VERSION ""

NS_ :

BS_:

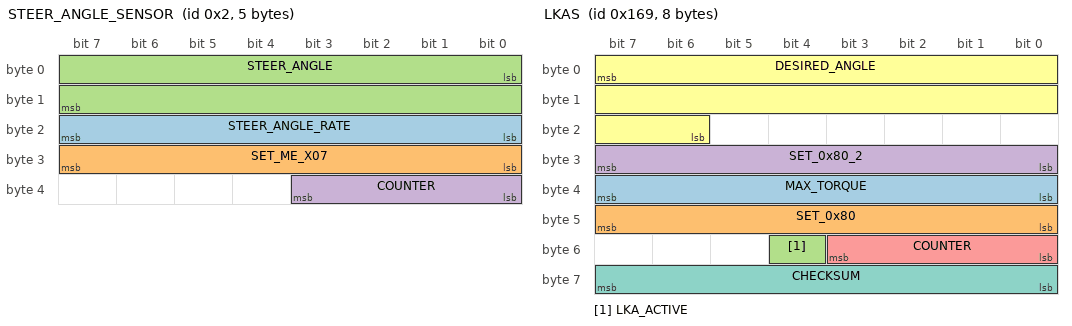
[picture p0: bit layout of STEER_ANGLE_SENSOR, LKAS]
BO_ 2 STEER_ANGLE_SENSOR: 5 XXX
 SG_ STEER_ANGLE_RATE : 16|8@1+ (1,0) [0|255] "" XXX
 SG_ SET_ME_X07 : 24|8@1+ (1,0) [0|255] "" XXX
 SG_ STEER_ANGLE : 0|16@1- (-0.1,0) [0|65535] "" XXX
 SG_ COUNTER : 32|4@1+ (1,0) [0|15] "" XXX

BO_ 361 LKAS: 8 XXX
 SG_ MAX_TORQUE : 39|8@0+ (0.01,0) [0|255] "Nm" XXX
 SG_ SET_0x80 : 47|8@0+ (1,0) [0|255] "" XXX
 SG_ LKA_ACTIVE : 52|1@0+ (1,0) [0|15] "" XXX
 SG_ SET_0x80_2 : 31|8@0+ (1,0) [0|255] "" XXX
 SG_ COUNTER : 51|4@0+ (1,0) [0|15] "" XXX
 SG_ DESIRED_ANGLE : 7|18@0+ (-0.01,1310) [-1311.43|1310] "" XXX
 SG_ CHECKSUM : 63|8@0+ (1,0) [0|255] "" XXX

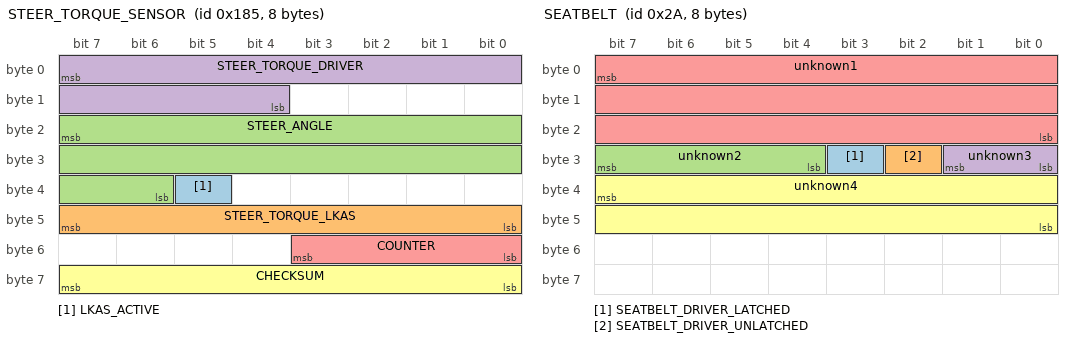
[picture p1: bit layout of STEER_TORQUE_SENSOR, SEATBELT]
BO_ 389 STEER_TORQUE_SENSOR: 8 XXX
 SG_ LKAS_ACTIVE : 37|1@0+ (1,0) [0|3] "" XXX
 SG_ STEER_TORQUE_LKAS : 47|8@0+ (1,0) [0|255] "" XXX
 SG_ STEER_ANGLE : 23|18@0+ (-0.01,1310) [0|262143] "" XXX
 SG_ STEER_TORQUE_DRIVER : 7|12@0+ (-0.01,20.47) [0|4095] "Nm" XXX
 SG_ COUNTER : 51|4@0+ (1,0) [0|15] "" XXX
 SG_ CHECKSUM : 63|8@0+ (1,0) [0|127] "" XXX

BO_ 645 WHEEL_SPEEDS_REAR: 8 XXX
 SG_ WHEEL_SPEED_RR : 7|16@0+ (0.005,0) [0|65535] "KPH" XXX
 SG_ WHEEL_SPEED_RL : 23|16@0+ (0.005,0) [0|65535] "KPH" XXX

BO_ 689 PROPILOT_HUD: 8 XXX
 SG_ LARGE_WARNING_FLASHING : 9|1@0+ (1,0) [0|1] "" XXX
 SG_ SIDE_RADAR_ERROR_FLASHING1 : 10|1@0+ (1,0) [0|1] "" XXX
 SG_ SIDE_RADAR_ERROR_FLASHING2 : 11|1@0+ (1,0) [0|1] "" XXX
 SG_ RIGHT_LANE_YELLOW_FLASH : 12|1@0+ (1,0) [0|1] "" XXX
 SG_ LEFT_LANE_YELLOW_FLASH : 13|1@0+ (1,0) [0|1] "" XXX
 SG_ LEAD_CAR : 14|1@0+ (1,0) [0|1] "" XXX
 SG_ LEAD_CAR_ERROR : 15|1@0+ (1,0) [0|1] "" XXX
 SG_ FRONT_RADAR_ERROR : 16|1@0+ (1,0) [0|1] "" XXX
 SG_ FRONT_RADAR_ERROR_FLASHING : 17|1@0+ (1,0) [0|1] "" XXX
 SG_ RIGHT_LANE_GREEN : 24|1@0+ (1,0) [0|1] "" XXX
 SG_ LEFT_LANE_GREEN : 25|1@0+ (1,0) [0|1] "" XXX
 SG_ SIDE_RADAR_ERROR_FLASHING3 : 27|1@0+ (1,0) [0|1] "" XXX
 SG_ LKAS_ERROR_FLASHING : 29|1@0+ (1,0) [0|1] "" XXX
 SG_ SAFETY_SHIELD_ACTIVE : 44|1@0+ (1,0) [0|1] "" XXX
 SG_ LARGE_STEERING_WHEEL_ICON : 61|2@0+ (1,0) [0|3] "" XXX
 SG_ RIGHT_LANE_GREEN_FLASH : 62|1@0+ (1,0) [0|1] "" XXX
 SG_ LEFT_LANE_GREEN_FLASH : 63|1@0+ (1,0) [0|1] "" XXX
 SG_ FOLLOW_DISTANCE : 3|2@0+ (1,0) [0|3] "" XXX
 SG_ AUDIBLE_TONE : 47|3@0+ (1,0) [0|8] "" XXX
 SG_ SPEED_SET_ICON : 7|2@0+ (1,0) [0|3] "" XXX
 SG_ SMALL_STEERING_WHEEL_ICON : 42|3@0+ (1,0) [0|7] "" XXX
 SG_ SET_SPEED : 39|8@0+ (1,0) [0|255] "" XXX
 SG_ unknown02 : 1|2@0+ (1,0) [0|3] "" XXX
 SG_ unknown05 : 5|2@0+ (1,0) [0|3] "" XXX
 SG_ unknown08 : 8|7@0+ (1,0) [0|63] "" XXX
 SG_ unknown26 : 26|1@0+ (1,0) [0|1] "" XXX
 SG_ unknown28 : 28|1@0+ (1,0) [0|1] "" XXX
 SG_ unknown31 : 31|2@0+ (1,0) [0|3] "" XXX
 SG_ unknown43 : 43|1@0+ (1,0) [0|1] "" XXX
 SG_ unknown55 : 55|8@0+ (1,0) [0|63] "" XXX
 SG_ unknown59 : 59|4@0+ (1,0) [0|15] "" XXX

BO_ 783 CRUISE_STATE: 3 XXX
 SG_ CRUISE_ENABLED : 3|1@0+ (1,0) [0|1] "" XXX

BO_ 1228 PROPILOT_HUD_INFO_MSG: 8 XXX
 SG_ NA_HIGH_ACCEL_TEMP : 0|1@0+ (1,0) [0|1] "" XXX
 SG_ SIDE_RADAR_NA_HIGH_CABIN_TEMP : 8|1@0+ (1,0) [0|1] "" XXX
 SG_ SIDE_RADAR_MALFUNCTION : 11|1@0+ (1,0) [0|1] "" XXX
 SG_ LKAS_MALFUNCTION : 12|1@0+ (1,0) [0|1] "" XXX
 SG_ FRONT_RADAR_MALFUNCTION : 13|1@0+ (1,0) [0|1] "" XXX
 SG_ SIDE_RADAR_NA_CLEAN_REAR_CAMERA : 14|1@0+ (1,0) [0|1] "" XXX
 SG_ NA_POOR_ROAD_CONDITIONS : 16|1@0+ (1,0) [0|1] "" XXX
 SG_ CURRENTLY_UNAVAILABLE : 17|1@0+ (1,0) [0|1] "" XXX
 SG_ SAFETY_SHIELD_OFF : 18|1@0+ (1,0) [0|1] "" XXX
 SG_ FRONT_COLLISION_NA_FRONT_RADAR_OBSTRUCTION : 20|1@0+ (1,0) [0|1] "" XXX
 SG_ PEDAL_MISSAPPLICATION_SYSTEM_ACTIVATED : 24|1@0+ (1,0) [0|1] "" XXX
 SG_ SIDE_IMPACT_NA_RADAR_OBSTRUCTION : 25|1@0+ (1,0) [0|1] "" XXX
 SG_ WARNING_DO_NOT_ENTER : 33|1@0+ (1,0) [0|1] "" XXX
 SG_ SIDE_IMPACT_SYSTEM_OFF : 34|1@0+ (1,0) [0|1] "" XXX
 SG_ SIDE_IMPACT_MALFUNCTION : 35|1@0+ (1,0) [0|1] "" XXX
 SG_ FRONT_COLLISION_MALFUNCTION : 36|1@0+ (1,0) [0|1] "" XXX
 SG_ SIDE_RADAR_MALFUNCTION2 : 37|1@0+ (1,0) [0|1] "" XXX
 SG_ LKAS_MALFUNCTION2 : 38|1@0+ (1,0) [0|1] "" XXX
 SG_ FRONT_RADAR_MALFUNCTION2 : 39|1@0+ (1,0) [0|1] "" XXX
 SG_ PROPILOT_NA_MSGS : 42|3@0+ (1,0) [0|7] "" XXX
 SG_ BOTTOM_MSG : 45|3@0+ (1,0) [0|7] "" XXX
 SG_ HANDS_ON_WHEEL_WARNING : 47|1@0+ (1,0) [0|1] "" XXX
 SG_ WARNING_STEP_ON_BRAKE_NOW : 51|1@0+ (1,0) [0|1] "" XXX
 SG_ PROPILOT_NA_FRONT_CAMERA_OBSTRUCTED : 52|1@0+ (1,0) [0|1] "" XXX
 SG_ PROPILOT_NA_HIGH_CABIN_TEMP : 53|1@0+ (1,0) [0|1] "" XXX
 SG_ WARNING_PROPILOT_MALFUNCTION : 54|1@0+ (1,0) [0|3] "" XXX
 SG_ ACC_UNAVAILABLE_HIGH_CABIN_TEMP : 62|1@0+ (1,0) [0|1] "" XXX
 SG_ ACC_NA_FRONT_CAMERA_IMPARED : 63|1@0+ (1,0) [0|1] "" XXX
 SG_ unknown07 : 7|7@0+ (1,0) [0|127] "" XXX
 SG_ unknown10 : 10|2@0+ (1,0) [0|3] "" XXX
 SG_ unknown15 : 15|1@0+ (1,0) [0|1] "" XXX
 SG_ unknown23 : 23|3@0+ (1,0) [0|7] "" XXX
 SG_ unknown19 : 19|1@0+ (1,0) [0|1] "" XXX
 SG_ unknown31 : 31|6@0+ (1,0) [0|63] "" XXX
 SG_ unknown32 : 32|1@0+ (1,0) [0|1] "" XXX
 SG_ unknown46 : 46|1@0+ (1,0) [0|1] "" XXX
 SG_ unknown50 : 50|3@0+ (1,0) [0|7] "" XXX
 SG_ unknown55 : 55|1@0+ (1,0) [0|1] "" XXX
 SG_ unknown61 : 61|6@0+ (1,0) [0|63] "" XXX

BO_ 1227 LKAS_SETTINGS: 8 XXX
 SG_ LKAS_ENABLED : 51|1@0+ (1,0) [0|1] "" XXX

BO_ 42 SEATBELT: 8 XXX
 SG_ SEATBELT_DRIVER_LATCHED : 27|1@1+ (1,0) [0|3] "" XXX
 SG_ SEATBELT_DRIVER_UNLATCHED : 26|1@0+ (1,0) [0|1] "" XXX
 SG_ unknown2 : 31|4@0+ (1,0) [0|15] "" XXX
 SG_ unknown3 : 24|2@1+ (1,0) [0|3] "" XXX
 SG_ unknown1 : 7|24@0+ (1,0) [0|16777215] "" XXX
 SG_ unknown4 : 39|16@0+ (1,0) [0|65535] "" XXX

BO_ 460 BRAKE_PEDAL: 8 XXX
 SG_ BRAKE_PEDAL : 7|8@0+ (1,0) [0|256] "" XXX

BO_ 569 CRUISE_THROTTLE: 8 XXX
 SG_ GAS_PEDAL_INVERTED : 15|8@0+ (1,0) [0|255] "" XXX
 SG_ GAS_PEDAL : 7|8@0+ (1,0) [0|255] "" XXX
 SG_ CRUISE_AVAILABLE : 17|1@0+ (1,0) [0|1] "" XXX
 SG_ unsure1 : 23|6@0+ (1,0) [0|63] "" XXX
 SG_ unsure2 : 16|1@0+ (1,0) [0|1] "" XXX
 SG_ unsure3 : 31|2@0+ (1,0) [0|3] "" XXX
 SG_ NO_BUTTON_PRESSED : 29|1@0+ (1,0) [0|1] "" XXX
 SG_ RES_BUTTON : 28|1@0+ (1,0) [0|1] "" XXX
 SG_ SET_BUTTON : 27|1@0+ (1,0) [0|1] "" XXX
 SG_ FOLLOW_DISTANCE_BUTTON : 26|1@0+ (1,0) [0|1] "" XXX
 SG_ CANCEL_BUTTON : 25|1@0+ (1,0) [0|1] "" XXX
 SG_ PROPILOT_BUTTON : 24|1@0+ (1,0) [0|1] "" XXX
 SG_ USER_BRAKE_PRESSED : 37|1@0+ (1,0) [0|1] "" XXX
 SG_ COUNTER : 32|2@1+ (1,0) [0|3] "" XXX
 SG_ unsure5 : 47|8@0+ (1,0) [0|255] "" XXX
 SG_ unsure6 : 55|8@0+ (1,0) [0|255] "" XXX
 SG_ unsure7 : 63|8@0+ (1,0) [0|255] "" XXX

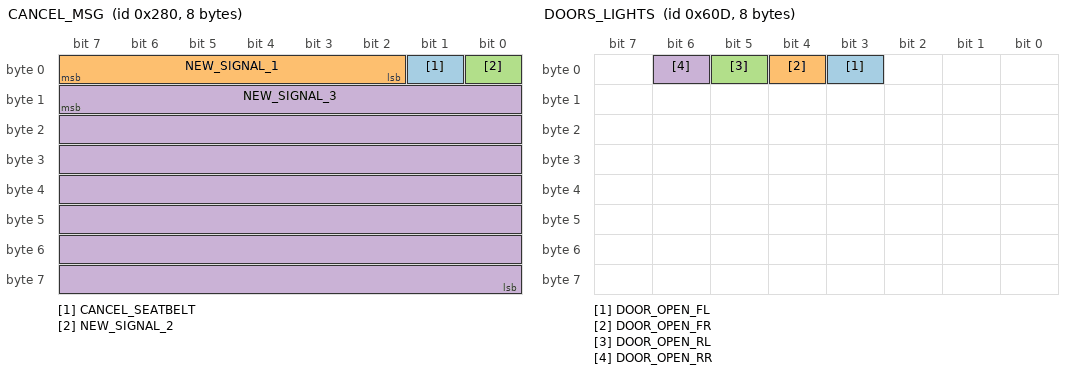
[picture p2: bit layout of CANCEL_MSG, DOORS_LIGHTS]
BO_ 640 CANCEL_MSG: 8 XXX
  SG_ CANCEL_SEATBELT : 1|1@0+ (1,0) [0|1] "" XXX
  SG_ NEW_SIGNAL_1 : 7|6@0+ (1,0) [0|63] "" XXX
  SG_ NEW_SIGNAL_2 : 0|1@0+ (1,0) [0|1] "" XXX
  SG_ NEW_SIGNAL_3 : 15|56@0+ (1,0) [0|72057594037927940] "" XXX

BO_ 644 WHEEL_SPEEDS_FRONT: 8 XXX
 SG_ WHEEL_SPEED_FR : 7|16@0+ (0.005,0) [0|65535] "KPH" XXX
 SG_ WHEEL_SPEED_FL : 23|16@0+ (0.005,0) [0|65535] "KPH" XXX

BO_ 852 ESP: 8 XXX
 SG_ ESP_DISABLED : 38|1@0+ (1,0) [0|1] "" XXX

BO_ 853 HUD_SETTINGS: 8 XXX
 SG_ SPEED_MPH : 37|1@0+ (1,0) [0|1] "" XXX

BO_ 856 LIGHTS: 8 XXX
 SG_ LEFT_BLINKER : 17|1@0+ (1,0) [0|1] "" XXX
 SG_ RIGHT_BLINKER : 18|1@0+ (1,0) [0|1] "" XXX

BO_ 1057 GEARBOX: 3 XXX
 SG_ GEAR_SHIFTER : 5|3@0+ (1,0) [0|255] "" XXX

BO_ 1549 DOORS_LIGHTS: 8 XXX
 SG_ DOOR_OPEN_FL : 3|1@0+ (1,0) [0|1] "" XXX
 SG_ DOOR_OPEN_FR : 4|1@0+ (1,0) [0|1] "" XXX
 SG_ DOOR_OPEN_RL : 5|1@0+ (1,0) [0|1] "" XXX
 SG_ DOOR_OPEN_RR : 6|1@0+ (1,0) [0|1] "" XXX

CM_ SG_ 129 SteeringAngle "Steering wheel angle: positive is right and negative is left";
CM_ SG_ 513 AcceleratorPos "processed interpretation of AcceleratorPedalSensor values";
CM_ SG_ 1072 FuelTankSensorLeft "lower sensor values indicate a more full tank";
VAL_ 870 AWV_Text 0 "kein_Text" 1 "FrontAssist_aus" 2 "FrontAssist_startet" 3 "FrontAssist_Warnung" 4 "FrontAssist_Sens_reinig" 5 "FrontAssist_Failure" 6 "FrontAssist_Demo" 7 "Vorhalt" 8 "Bremsung_wird_gerade_durchgefuehrt" 9 "Sensor_not_verfuegbar" 10 "Sensor_reinigen" 11 "Service_notwendig_Failure" 12 "Funktion_vom_Fahrer_deactivated" 13 "Funktion_vom_Fahrer_activated" 14 "FrontAssist_zur_Zeit_not_verfuegbar__rev_Failure";
VAL_ 870 AWV_1_Freigabe 0 "nicht_freigegeben" 1 "freigegeben";
VAL_ 870 AWV_1_Prefill 0 "keine_Prefill_Anf" 1 "Prefill_Anf";
VAL_ 870 AWV_1_Parameter 0 "Defaultparametersatz" 1 "Par_leicht_erh_Empf" 2 "Par_erh_Empf" 3 "Par_hoechster_Empf";
VAL_ 870 AWV_only 0 "ACC_und_AWV_verbaut" 1 "AWV_ohne_ACC_verbaut";
VAL_ 870 AWV_CityANB_Auspraegung 0 "autom_Bremsung_im_ges_vBereich" 1 "autom_Bremsung_im_def_vBereich";
VAL_ 870 AWV_Halten 0 "keine_Anforderung" 1 "Anforderung_das_Fzg_im_Stillstand_zu_halten";
VAL_ 870 ANB_Teilbremsung_Freigabe 0 "Teilbremsung_nicht_freigegeben" 1 "Teilbremsung_freigegeben";
VAL_ 870 AWV_2_Status 0 "Lampe_aus" 1 "Lampe_ein";
VAL_ 870 AWV_2_Fehler 0 "Lampe_aus" 1 "Lampe_ein";
VAL_ 870 AWV_2_SU_Warnzeit 0 "frueh" 1 "normal" 2 "spaet" 3 "adaptiv";
VAL_ 870 AWV_2_SU_Bremsruck 0 "Bremsruck_deaktiviert" 1 "Bremsruck_aktiviert";
VAL_ 870 AWV_2_SU_Gong 0 "Gong_deaktiviert" 1 "Gong_aktiviert";
VAL_ 870 AWV_2_SU_Lampe 0 "Lampe_deaktiviert" 1 "Lampe_aktiviert";
VAL_ 870 AWV_2_Umfeldwarn 0 "keine_Warnung" 1 "Warnung";
VAL_ 870 AWV_2_Freigabe 0 "keine_Ruckfreigabe" 1 "Ruckfreigabe";
VAL_ 870 AWV_2_Ruckprofil 0 "kein_Ruck" 1 "Ruckprofil_1" 2 "Ruckprofil_2" 3 "Ruckprofil_3" 4 "Ruckprofil_4" 5 "Ruckprofil_5" 6 "not_erlaubt" 7 "not_erlaubt";
VAL_ 870 AWV_2_Warnton 0 "Aus" 1 "Ein";
VAL_ 870 AWV_2_Warnsymbol 0 "Aus" 1 "Ein";
VAL_ 870 AWV_Infoton 0 "Aus" 1 "Ein";
VAL_ 870 AWV_2_Gurtstraffer 0 "Gurt_not_straffen" 1 "Gurt_straffen";
VAL_ 870 AWV_Konfiguration_Menueanf 0 "Menue_deaktivieren" 1 "Menue_aktivieren";
VAL_ 870 AWV_Konfiguration_Vorw_Menueanf 0 "Menue_deaktivieren" 1 "Menue_aktivieren";
VAL_ 870 AWV_Konfiguration_Status 0 "AWV_inaktiv" 1 "AWV_aktiv";
VAL_ 870 AWV_Konfiguration_Vorw_Status 0 "AWV_Vorwarnung_inaktiv" 1 "AWV_Vorwarnung_aktiv";
VAL_ 870 AWV_2_Abstandswarnung 0 "kein_Warnhinweis" 1 "Warnhinweis";
VAL_ 870 ANB_Zielbremsung_Freigabe 0 "Zielbremsung_nicht_freigegeben" 1 "Zielbremsung_freigegeben";
VAL_ 870 ANB_CM_Anforderung 0 "keine_Anforderung" 1 "Anforderung_aktiv";

VAL_ 872 ACS_Sta_ADR 2 "ADR_passiv" 0 "ADR_nicht_aktiv" 1 "ADR_aktiv" 3 "irrev_Fehler" ;
VAL_ 872 ACS_ADR_Schub 1 "Verz_begr_auf_Schub" 0 "Verz_nicht_begr_auf_Schub" ;
VAL_ 872 ACS_Schubabsch 1 "SA_nicht_zulaessig" 0 "SA_zulaessig" ;
VAL_ 872 ACS_StSt_Info 3 "Systemfehler" 0 "Motorlauf_nn" 1 "Stoppverbot_Motoranlauf_nn" 2 "Motoranlauf_notwendig" ;
VAL_ 872 ACS_MomEingriff 1 "MomEingr_verhindern" 0 "keine_Beeinfl_MomEingr_Mot" ;
VAL_ 872 ACS_Typ_ACC 0 "Basis_ACC" 1 "ACC_mit_FollowToStop" 3 "frei" 2 "frei" ;
VAL_ 872 ACS_FreigSollB 0 "Sollbeschl_nicht_freigeg" 1 "Sollbeschl_freigeg" ;
VAL_ 872 ACS_Sollbeschl 2046 "ADR_nicht_aktiv" 2047 "Fehler" ;
VAL_ 872 ACS_Anhaltewunsch 0 "kein_Haltewunsch" 1 "Fzg_haelt_an" ;
VAL_ 872 ACS_Fehler 1 "Fehlerspeichereintrag" 0 "kein_Fehlerspeichereintrag" ;
VAL_ 872 ACS_zul_Regelabw 254 "ADR_nicht_aktiv" 255 "Fehler" ;
VAL_ 872 ACS_max_AendGrad 254 "Neutralwert" 0 "Neutralwert" 255 "Fehler" ;

VAL_ 978 LH2_Sta_HCA 0 "disabled" 1 "initializing" 2 "fault" 3 "ready" 4 "rejected" 5 "active";
VAL_ 1088 Waehlhebelposition__Getriebe_1_ 8 "P" 7 "R" 6 "N" 5 "D" 9 "U" 12 "S" 14 "T" 10 "T" 11 "T";

VAL_ 1386 ACA_StaACC 6 "ACC_rev_aus" 0 "Hauptschalter_aus" 4 "ACC_im_Hintergrund" 3 "ACC_aktiv" 1 "Reserve" 2 "ACC_passiv" 7 "ACC_irrev_aus" 5 "frei" ;
VAL_ 1386 ACA_ID_StaACC 0 "keine_Anzeige" ;
VAL_ 1386 ACA_Fahrerhinw 1 "Ein" 0 "Aus" ;
VAL_ 1386 ACA_AnzDisplay 1 "Anzeige_erw" 0 "Anzeige_nicht_erw" ;
VAL_ 1386 ACA_Zeitluecke 3 "Zeitluecke3" 10 "Zeitluecke10" 4 "Zeitluecke4" 14 "Zeitluecke14" 11 "Zeitluecke11" 2 "Zeitluecke2" 13 "Zeitluecke13" 9 "Zeitluecke9" 1 "Zeitluecke1" 8 "Zeitluecke8" 5 "Zeitluecke5" 15 "Zeitluecke15" 0 "nicht_definiert" 12 "Zeitluecke12" 6 "Zeitluecke6" 7 "Zeitluecke7" ;
VAL_ 1386 ACA_V_Wunsch 255 "kein_Wert_im_Speicher" ;
VAL_ 1386 ACA_kmh_mph 0 "km_h" 1 "mph" ;
VAL_ 1386 ACA_Akustik1 0 "kein_Gong" 1 "Gong" ;
VAL_ 1386 ACA_Akustik2 0 "kein_Summer" 1 "Summer" ;
VAL_ 1386 ACA_PrioDisp 1 "mittlere_Prio" 3 "keine_Anzeige_Anf" 0 "hohe_Prio" 2 "niedrige_Prio" ;
VAL_ 1386 ACA_gemZeitl 6 "Zeitluecke6" 2 "Zeitluecke2" 7 "Zeitluecke7" 13 "Zeitluecke13" 11 "Zeitluecke11" 4 "Zeitluecke4" 8 "Zeitluecke8" 12 "Zeitluecke12" 10 "Zeitluecke10" 0 "Kein_Objekt_erfasst" 1 "Zeitluecke1" 3 "Zeitluecke3" 9 "Zeitluecke9" 15 "Zeitluecke15" 14 "Zeitluecke14" 5 "Zeitluecke5" ;
VAL_ 1386 ACA_ACC_Verz 0 "ACC_verzoegert_nicht" 1 "ACC_verzoegert" ;
VAL_ 1386 ACA_StaGRA 3 "GRA_aktiv" 4 "GRA_uebertreten" 2 "GRA_passiv" 0 "Hauptschalter_aus" 6 "frei" 7 "GRA_Fehler" 1 "Reserve" 5 "frei" ;
VAL_ 1386 ACA_ID_StaGRA 0 "keine_Anzeige" ;
VAL_ 1386 ACA_Codierung 0 "ACC" 1 "GRA" ;
VAL_ 1386 ACA_Tachokranz 0 "nicht_beleuchtet" 1 "beleuchtet" ;
VAL_ 1386 ACA_Aend_Zeitluecke 1 "Anzeige_angef" 0 "keine_Anzeige" ;

VAL_ 1472 EP1_Fehler_Sta 0 "volle_Funktion" 1 "linke_Seite_fehlerhaft" 2 "rechte_Seite_fehlerhaft" 3 "beide_Seiten_fehlerhaft";
VAL_ 1472 EP1_Sta_EPB 0 "Bremse_geoeffnet" 1 "Bremse_geschlossen";
VAL_ 1472 EP1_Sta_Schalter 0 "volle_Funktion" 1 "Schalter_ausser_Funktion";
VAL_ 1472 EP1_Spannkraft 31 "Fehler";
VAL_ 1472 EP1_Schalterinfo 0 "keine_Fahreranforderung" 1 "Fahreranforderung_oeffnen" 2 "Fahreranforderung_schliessen" 3 "Schalterfehler";
VAL_ 1472 EP1_Sta_NWS 0 "volle_Funktion" 1 "keine_Funktion";
VAL_ 1472 EP1_Fehlereintr 0 "kein_Fehlerspeichereintrag" 1 "Fehlerspeichereintrag";
VAL_ 1472 EP1_Freigabe_Ver 0 "Verzoegerungsanf_nicht_freigegeb" 1 "Verzoegerungsanf_freigegeben";
VAL_ 1472 EP1_AutoHold_zul 0 "Pers_nicht_zulaessig" 1 "Pers_zulaessig";
VAL_ 1472 EP1_AutoHold_aktiv 0 "nein" 1 "ja";
VAL_ 1472 EP1_SleepInd 0 "CAN_wird_benoetigt" 1 "Sleep_bereit";
VAL_ 1472 EP1_Status_Kl_15 0 "Kl_15_aus" 1 "Kl_15_ein";
VAL_ 1472 EP1_Lampe_AutoP 0 "Lampe_aus" 1 "Lampe_ein";
VAL_ 1472 EP1_Bremslicht 0 "Aus" 1 "Ein";
VAL_ 1472 EP1_Warnton1 0 "Aus" 1 "Ein";
VAL_ 1472 EP1_Warnton2 0 "Aus" 1 "Ein";
VAL_ 1472 EP1_AnfShLock 0 "Aus" 1 "Ein";
VAL_ 1472 EPB_Autoholdlampe 0 "Lampe_aus" 1 "Lampe_ein";
VAL_ 1472 EP1_QualNeigWi 0 "gueltiger_Wert" 1 "Ersatz_Init_oder_Fehlerwert";
VAL_ 1472 EP1_KuppModBer 0 "Kuppsensor_aus_Modbereich" 1 "Kupplsensor_im_Modbereich" 2 "Sensorsignal_ungenau" 3 "Sensor_defekt";
VAL_ 1472 EP1_HydrHalten 0 "Fzg_nicht_hydr_geh" 1 "Fzg_hydr_geh";
VAL_ 1472 EP1_Fkt_Lampe 0 "Lampe_aus" 1 "Lampe_ein";
VAL_ 1472 EP1_Warnton 0 "Warnton_aus" 1 "Warnton_an";
VAL_ 1472 EP1_Fehler_BKL 0 "BKL_aus" 1 "BKL_an";
VAL_ 1472 EP1_Fehler_gelb 0 "Lampe_aus" 1 "Lampe_ein";
